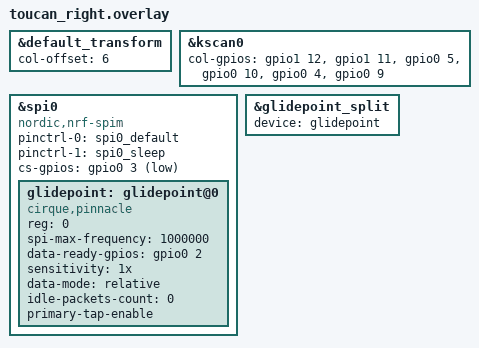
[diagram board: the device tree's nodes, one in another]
#include "toucan.dtsi"
#include "toucan_spi.dtsi"

&default_transform {
	col-offset = <6>;
};

&kscan0 {
	col-gpios
		= <&gpio1 12 GPIO_ACTIVE_HIGH>
		, <&gpio1 11 GPIO_ACTIVE_HIGH>
		, <&gpio0 5 GPIO_ACTIVE_HIGH>
		, <&gpio0 10 GPIO_ACTIVE_HIGH>
		, <&gpio0 4 GPIO_ACTIVE_HIGH>
		, <&gpio0 9 GPIO_ACTIVE_HIGH>
		;
};

&spi0 {
	compatible = "nordic,nrf-spim";
	status = "okay";
	pinctrl-0 = <&spi0_default>;
	pinctrl-1 = <&spi0_sleep>;
	pinctrl-names = "default", "sleep";
	/* CS pull-up keeps !asserted when SPI is asleep (beekeeb#23 board-dependent). */
	cs-gpios = <&gpio0 3 (GPIO_ACTIVE_LOW | GPIO_PULL_UP)>;

	glidepoint: glidepoint@0 {
		compatible = "cirque,pinnacle";
		reg = <0>;
		spi-max-frequency = <1000000>;
		status = "okay";
		/* HW_DR is active-high on this board. */
		data-ready-gpios = <&gpio0 2 GPIO_ACTIVE_HIGH>;
		/* 1x = most sensitive (2x was weak for dry fingertips). */
		sensitivity = "1x";
		data-mode = "relative";
		idle-packets-count = <0>;
		primary-tap-enable;
		/* No DT sleep-mode-enable — host owns Sleep/Shutdown (cirque/). */
	};
};

&glidepoint_split {
	device = <&glidepoint>;
};
